VERSION ""

NS_ :

BS_:

BU_: ECU

VAL_TABLE_ Engine_Limiting_Functions 0 "None" 1 "Hard Rev Limiting" 2 "Soft Rev Limiting" 3 "Spark Retard Limiting" 4 "Boost Limiting" 5 "Nitrous Retard" 6 "Flat Shift" 7 "Traction Control" 8 "Launch Control" 9 "Anti-Lag" 10 "Engine Protection" 11 "3-Step Launch" 12 "Rolling Launch" 13 "Burn Out" 14 "Water Inj." 15 "Gear Shift Cut" 16 "RPM Window Switch" 17 "Torque Management" 18 "Overrun Boost" 19 "Idle Control" ;

VAL_TABLE_ Haltech_Special_Values_Gear 0 "Neutral" 1 "1st" 2 "2nd" 3 "3rd" 4 "4th" 5 "5th" 6 "6th" 7 "7th" 8 "8th" 9 "9th" 10 "10th" 11 "11th" 12 "12th" -1 "Reverse" ;

VAL_TABLE_ Traction_Control_States 0 "Disabled" 1 "Enabled" 2 "Active" 3 "Active & Enabled" ;

VAL_TABLE_ Boolean_States 0 "Off" 1 "On" ;

VAL_TABLE_ CAN_Error_Values 0 "Error" ;

VAL_TABLE_ Exhausted_Cutout_States -1 "Input Error" 0 "Disabled" 1 "Closed" 2 "Opening" 3 "Open" 4 "Closing" 5 "Paused Part Way" ;

VAL_TABLE_ Engine_Limiter_Method 0 "No Cut" 1 "Fuel" 2 "Ignition" 3 "Fuel and Ignition" ;

VAL_TABLE_ Cruise_Control_States 0 "Disabled" 1 "Inactive" 2 "Cruising" 3 "Accelerating" 4 "Decelerating" ;

VAL_TABLE_ Cruise_Control_Input_States 0 "Unused" 1 "Disable" 2 "Enable" 3 "Enable/Disable" 4 "Cancel" 8 "Set" 12 "Set/Cancel" 16 "Resume" 20 "Resume/Cancel" 32 "Accel" 64 "Decel" 76 "Set/Coast/Cancel" 84 "Resume/Coast/Cancel" 128 "Increment" 168 "Set/Accel/+" 176 "Resume/Accel/+" 256 "Decrement" 328 "Set/Coast/-" 336 "Resume/Coast/-" 512 "Rest Position" ;

VAL_TABLE_ ABS_States 0 "Not Armed" 1 "Armed" ;

VAL_TABLE_ ABS_Activity 0 "Inactive" 1 "Active" ;

VAL_TABLE_ ABS_Error 0 "OK" 1 "Error" ;

VAL_TABLE_ Pit_Lane_States 0 "Inactive" 1 "Active" ;

VAL_TABLE_ Pit_Lane_Error 0 "OK" 1 "Error" ;

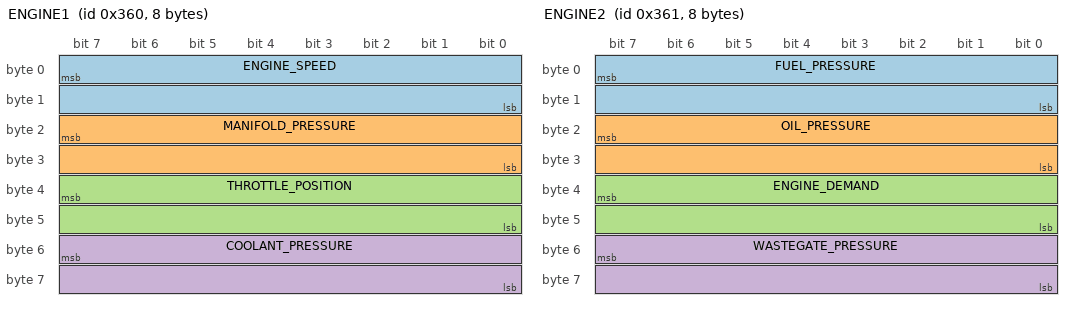
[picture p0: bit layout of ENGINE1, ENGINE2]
BO_ 864 ENGINE1: 8 ECU
 SG_ ENGINE_SPEED : 7|16@0+ (1,0) [0|65535] "RPM" ECU
 SG_ MANIFOLD_PRESSURE : 23|16@0+ (0.1,0) [0|6553.5] "kPa" ECU
 SG_ THROTTLE_POSITION : 39|16@0+ (0.1,0) [0|100] "%" ECU
 SG_ COOLANT_PRESSURE : 55|16@0+ (0.1,-101.3) [-101.3|6452.2] "kPa" ECU

BO_ 865 ENGINE2: 8 ECU
 SG_ FUEL_PRESSURE : 7|16@0+ (0.1,-101.3) [-101.3|6452.2] "kPa" ECU
 SG_ OIL_PRESSURE : 23|16@0+ (0.1,-101.3) [-101.3|6452.2] "kPa" ECU
 SG_ ENGINE_DEMAND : 39|16@0+ (0.1,0) [0|100] "%" ECU
 SG_ WASTEGATE_PRESSURE : 55|16@0+ (0.1,-101.3) [-101.3|6452.2] "kPa" ECU

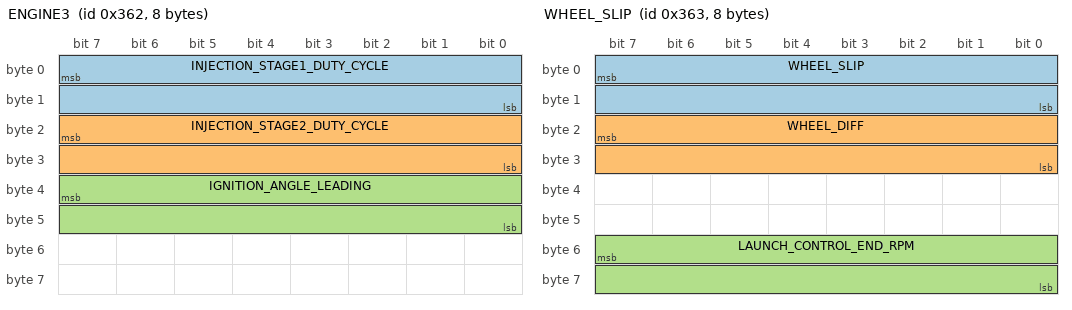
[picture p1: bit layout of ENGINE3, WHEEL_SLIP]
BO_ 866 ENGINE3: 8 ECU
 SG_ INJECTION_STAGE1_DUTY_CYCLE : 7|16@0+ (0.1,0) [0|100] "%" ECU
 SG_ INJECTION_STAGE2_DUTY_CYCLE : 23|16@0+ (0.1,0) [0|100] "%" ECU
 SG_ IGNITION_ANGLE_LEADING : 39|16@0- (0.1,0) [-3276.8|3276.7] "°" ECU

BO_ 867 WHEEL_SLIP: 8 ECU
 SG_ WHEEL_SLIP : 7|16@0- (0.1,0) [-3276.8|3276.7] "km/h" ECU
 SG_ WHEEL_DIFF : 23|16@0- (0.1,0) [-3276.8|3276.7] "km/h" ECU
 SG_ LAUNCH_CONTROL_END_RPM : 55|16@0+ (1,0) [0|65535] "RPM" ECU

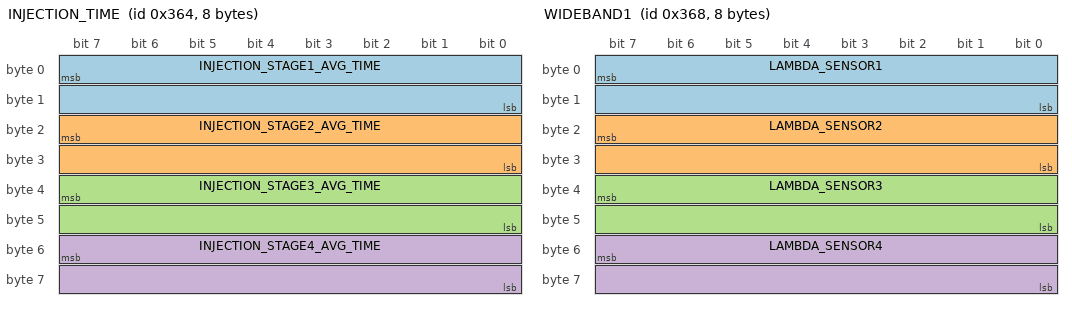
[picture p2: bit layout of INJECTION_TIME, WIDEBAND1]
BO_ 868 INJECTION_TIME: 8 ECU
 SG_ INJECTION_STAGE1_AVG_TIME : 7|16@0+ (0.001,0) [0|65.535] "ms" ECU
 SG_ INJECTION_STAGE2_AVG_TIME : 23|16@0+ (0.001,0) [0|65.535] "ms" ECU
 SG_ INJECTION_STAGE3_AVG_TIME : 39|16@0+ (0.001,0) [0|65.535] "ms" ECU
 SG_ INJECTION_STAGE4_AVG_TIME : 55|16@0+ (0.001,0) [0|65.535] "ms" ECU

BO_ 872 WIDEBAND1: 8 ECU
 SG_ LAMBDA_SENSOR1 : 7|16@0+ (0.001,0) [0|65.535] "λ" ECU
 SG_ LAMBDA_SENSOR2 : 23|16@0+ (0.001,0) [0|65.535] "λ" ECU
 SG_ LAMBDA_SENSOR3 : 39|16@0+ (0.001,0) [0|65.535] "λ" ECU
 SG_ LAMBDA_SENSOR4 : 55|16@0+ (0.001,0) [0|65.535] "λ" ECU

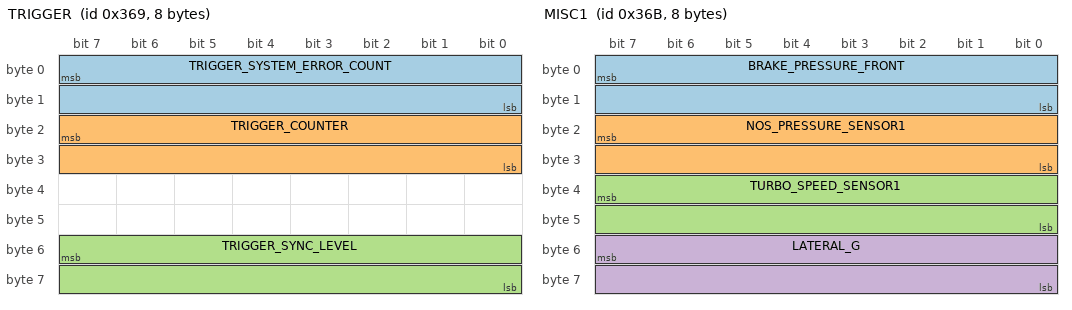
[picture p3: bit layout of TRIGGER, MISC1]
BO_ 873 TRIGGER: 8 ECU
 SG_ TRIGGER_SYSTEM_ERROR_COUNT : 7|16@0+ (1,0) [0|65535] "raw" ECU
 SG_ TRIGGER_COUNTER : 23|16@0+ (1,0) [0|65535] "raw" ECU
 SG_ TRIGGER_SYNC_LEVEL : 55|16@0+ (1,0) [0|65535] "raw" ECU

BO_ 874 KNOCK: 8 ECU
 SG_ KNOCK_LEVEL1 : 7|16@0+ (0.01,0) [0|655.35] "dB" ECU
 SG_ KNOCK_LEVEL2 : 23|16@0+ (0.01,0) [0|655.35] "dB" ECU

BO_ 875 MISC1: 8 ECU
 SG_ BRAKE_PRESSURE_FRONT : 7|16@0+ (1,-101.3) [-101.3|65433.7] "kPa" ECU
 SG_ NOS_PRESSURE_SENSOR1 : 23|16@0+ (0.22,-101.3) [-101.3|14316.4] "kPa" ECU
 SG_ TURBO_SPEED_SENSOR1 : 39|16@0+ (10,0) [0|655350] "RPM" ECU
 SG_ LATERAL_G : 55|16@0- (0.1,0) [-3276.8|3276.7] "m/s2" ECU

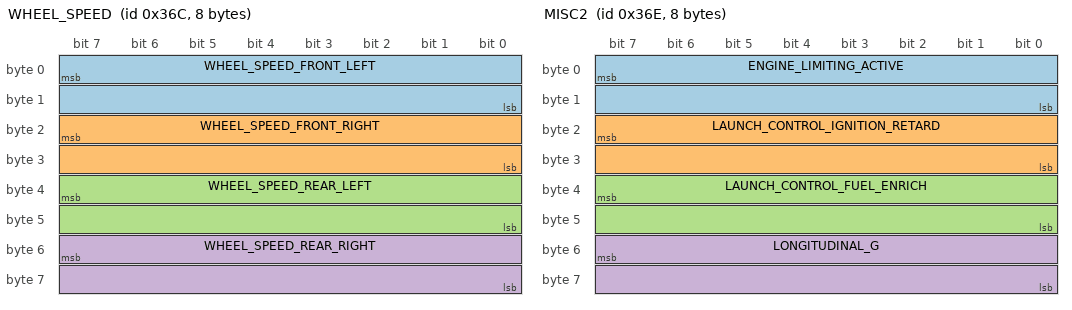
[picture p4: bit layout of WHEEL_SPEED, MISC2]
BO_ 876 WHEEL_SPEED: 8 ECU
 SG_ WHEEL_SPEED_FRONT_LEFT : 7|16@0+ (0.1,0) [0|6553.5] "km/h" ECU
 SG_ WHEEL_SPEED_FRONT_RIGHT : 23|16@0+ (0.1,0) [0|6553.5] "km/h" ECU
 SG_ WHEEL_SPEED_REAR_LEFT : 39|16@0+ (0.1,0) [0|6553.5] "km/h" ECU
 SG_ WHEEL_SPEED_REAR_RIGHT : 55|16@0+ (0.1,0) [0|6553.5] "km/h" ECU

BO_ 877 EXHAUST_CAM: 8 ECU
 SG_ EXHAUST_CAM_ANGLE1 : 39|16@0- (0.1,0) [-3276.8|3276.7] "°" ECU
 SG_ EXHAUST_CAM_ANGLE2 : 55|16@0- (0.1,0) [-3276.8|3276.7] "°" ECU

BO_ 878 MISC2: 8 ECU
 SG_ ENGINE_LIMITING_ACTIVE : 7|16@0+ (1,0) [0|1] "boolean" ECU
 SG_ LAUNCH_CONTROL_IGNITION_RETARD : 23|16@0- (0.1,0) [-3276.8|3276.7] "°" ECU
 SG_ LAUNCH_CONTROL_FUEL_ENRICH : 39|16@0- (0.1,0) [-3276.8|3276.7] "%" ECU
 SG_ LONGITUDINAL_G : 55|16@0- (0.1,0) [-3276.8|3276.7] "m/s2" ECU

BO_ 879 PWM_OUTPUT: 8 ECU
 SG_ GENERIC_OUTPUT1_DUTY_CYCLE : 7|16@0+ (0.1,0) [0|100] "%" ECU
 SG_ BOOST_CONTROL_OUTPUT : 23|16@0+ (0.1,0) [0|100] "%" ECU

BO_ 880 MISC3: 8 ECU
 SG_ VEHICLE_SPEED : 7|16@0+ (0.1,0) [0|6553.5] "km/h" ECU
 SG_ INTAKE_CAM_ANGLE1 : 39|16@0- (0.1,0) [-3276.8|3276.7] "°" ECU
 SG_ INTAKE_CAM_ANGLE2 : 55|16@0- (0.1,0) [-3276.8|3276.7] "°" ECU

BO_ 881 FUEL_FLOW: 8 ECU
 SG_ FUEL_FLOW : 7|16@0+ (1,0) [0|65535] "cc/min" ECU
 SG_ FUEL_FLOW_RETURN : 23|16@0+ (1,0) [0|65535] "cc/min" ECU

BO_ 882 MISC4: 8 ECU
 SG_ BATTERY_VOLTAGE : 7|16@0+ (0.1,0) [0|6553.5] "Volts" ECU
 SG_ TARGET_BOOST_LEVEL : 39|16@0+ (0.1,0) [0|6553.5] "kPa" ECU
 SG_ BAROMETRIC_PRESSURE : 55|16@0+ (0.1,0) [0|6553.5] "kPa" ECU

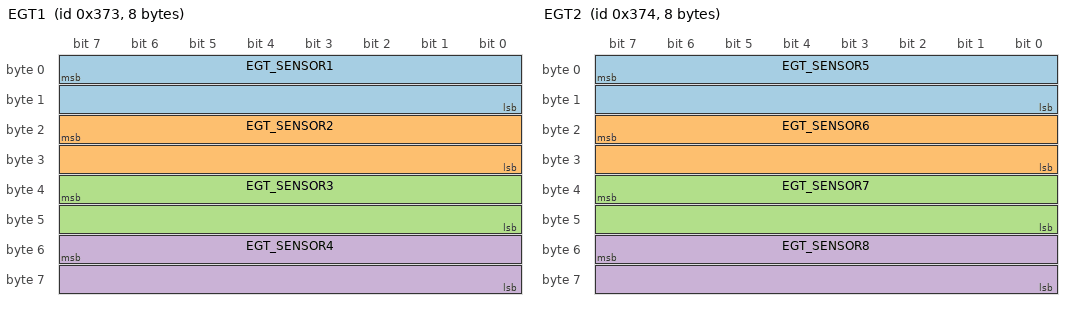
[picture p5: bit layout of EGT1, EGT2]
BO_ 883 EGT1: 8 ECU
 SG_ EGT_SENSOR1 : 7|16@0+ (0.1,0) [0|6553.5] "K" ECU
 SG_ EGT_SENSOR2 : 23|16@0+ (0.1,0) [0|6553.5] "K" ECU
 SG_ EGT_SENSOR3 : 39|16@0+ (0.1,0) [0|6553.5] "K" ECU
 SG_ EGT_SENSOR4 : 55|16@0+ (0.1,0) [0|6553.5] "K" ECU

BO_ 884 EGT2: 8 ECU
 SG_ EGT_SENSOR5 : 7|16@0+ (0.1,0) [0|6553.5] "K" ECU
 SG_ EGT_SENSOR6 : 23|16@0+ (0.1,0) [0|6553.5] "K" ECU
 SG_ EGT_SENSOR7 : 39|16@0+ (0.1,0) [0|6553.5] "K" ECU
 SG_ EGT_SENSOR8 : 55|16@0+ (0.1,0) [0|6553.5] "K" ECU

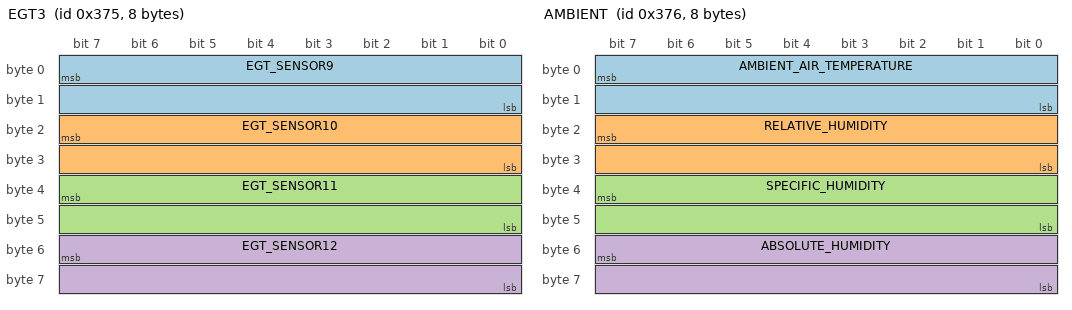
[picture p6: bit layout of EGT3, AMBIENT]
BO_ 885 EGT3: 8 ECU
 SG_ EGT_SENSOR9 : 7|16@0+ (0.1,0) [0|6553.5] "K" ECU
 SG_ EGT_SENSOR10 : 23|16@0+ (0.1,0) [0|6553.5] "K" ECU
 SG_ EGT_SENSOR11 : 39|16@0+ (0.1,0) [0|6553.5] "K" ECU
 SG_ EGT_SENSOR12 : 55|16@0+ (0.1,0) [0|6553.5] "K" ECU

BO_ 886 AMBIENT: 8 ECU
 SG_ AMBIENT_AIR_TEMPERATURE : 7|16@0+ (0.1,0) [0|6553.5] "K" ECU
 SG_ RELATIVE_HUMIDITY : 23|16@0- (0.1,0) [-3276.8|3276.7] "%" ECU
 SG_ SPECIFIC_HUMIDITY : 39|16@0+ (100,0) [0|6553500] "ppm" ECU
 SG_ ABSOLUTE_HUMIDITY : 55|16@0+ (0.1,0) [0|6553.5] "g/m3" ECU

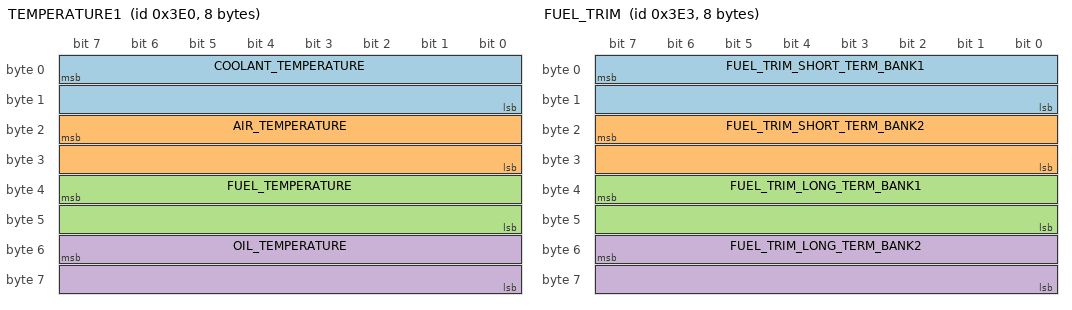
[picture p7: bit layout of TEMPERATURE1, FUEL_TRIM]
BO_ 992 TEMPERATURE1: 8 ECU
 SG_ COOLANT_TEMPERATURE : 7|16@0+ (0.1,0) [0|6553.5] "K" ECU
 SG_ AIR_TEMPERATURE : 23|16@0+ (0.1,0) [0|6553.5] "K" ECU
 SG_ FUEL_TEMPERATURE : 39|16@0+ (0.1,0) [0|6553.5] "K" ECU
 SG_ OIL_TEMPERATURE : 55|16@0+ (0.1,0) [0|6553.5] "K" ECU

BO_ 993 TEMPERATURE2: 8 ECU
 SG_ GEARBOX_OIL_TEMPERATURE : 7|16@0+ (0.1,0) [0|6553.5] "K" ECU
 SG_ DIFF_OIL_TEMPERATURE : 23|16@0+ (0.1,0) [0|6553.5] "K" ECU
 SG_ FUEL_COMPOSITION : 39|16@0+ (0.1,0) [0|100] "%" ECU

BO_ 994 FUEL_LEVEL: 8 ECU
 SG_ FUEL_LEVEL : 7|16@0+ (0.1,0) [0|6553.5] "L" ECU

BO_ 995 FUEL_TRIM: 8 ECU
 SG_ FUEL_TRIM_SHORT_TERM_BANK1 : 7|16@0- (0.1,0) [-3276.8|3276.7] "%" ECU
 SG_ FUEL_TRIM_SHORT_TERM_BANK2 : 23|16@0- (0.1,0) [-3276.8|3276.7] "%" ECU
 SG_ FUEL_TRIM_LONG_TERM_BANK1 : 39|16@0- (0.1,0) [-3276.8|3276.7] "%" ECU
 SG_ FUEL_TRIM_LONG_TERM_BANK2 : 55|16@0- (0.1,0) [-3276.8|3276.7] "%" ECU

BO_ 996 MISC5: 8 ECU
 SG_ NEUTRAL_SWITCH : 15|1@0+ (1,0) [0|1] "boolean" ECU
 SG_ REVERSE_SWITCH : 14|1@0+ (1,0) [0|1] "boolean" ECU
 SG_ GEAR_SWITCH : 13|1@0+ (1,0) [0|1] "boolean" ECU
 SG_ DECEL_CUT_ACTIVE : 12|1@0+ (1,0) [0|1] "boolean" ECU
 SG_ TRANSIENT_THROTTLE_ACTIVE : 11|1@0+ (1,0) [0|1] "boolean" ECU
 SG_ BRAKE_PEDAL_SWITCH : 10|1@0+ (1,0) [0|1] "boolean" ECU
 SG_ CLUTCH_SWITCH : 9|1@0+ (1,0) [0|1] "boolean" ECU
 SG_ OIL_PRESSURE_LIGHT : 8|1@0+ (1,0) [0|1] "boolean" ECU
 SG_ LAUNCH_CONTROL_ACTIVE : 23|1@0+ (1,0) [0|1] "boolean" ECU
 SG_ LAUNCH_CONTROL_SWITCH : 22|1@0+ (1,0) [0|1] "boolean" ECU
 SG_ AUX_RPM_LIMITER_ACTIVE : 21|1@0+ (1,0) [0|1] "boolean" ECU
 SG_ FLAT_SHIFT_SWITCH : 19|1@0+ (1,0) [0|1] "boolean" ECU
 SG_ TORQUE_REDUCTION_ACTIVE : 17|1@0+ (1,0) [0|1] "boolean" ECU
 SG_ TRACTION_CONTROL_ENABLED : 31|1@0+ (1,0) [0|1] "boolean" ECU
 SG_ TRACTION_CONTROL_ACTIVE : 30|1@0+ (1,0) [0|1] "boolean" ECU
 SG_ AIR_CON_REQUEST : 29|1@0+ (1,0) [0|1] "boolean" ECU
 SG_ AIR_CON_OUTPUT : 28|1@0+ (1,0) [0|1] "boolean" ECU
 SG_ THERMO_FAN4_ON : 27|1@0+ (1,0) [0|1] "boolean" ECU
 SG_ THERMO_FAN3_ON : 26|1@0+ (1,0) [0|1] "boolean" ECU
 SG_ THERMO_FAN2_ON : 25|1@0+ (1,0) [0|1] "boolean" ECU
 SG_ THERMO_FAN1_ON : 24|1@0+ (1,0) [0|1] "boolean" ECU
 SG_ ROTARY_TRIM_POT1 : 39|8@0- (1,0) [-128|127] "raw" ECU
 SG_ ROTARY_TRIM_POT2 : 47|8@0- (1,0) [-128|127] "raw" ECU
 SG_ ROTARY_TRIM_POT3 : 55|8@0- (1,0) [-128|127] "raw" ECU
 SG_ CHECK_ENGINE_LIGHT : 63|1@0+ (1,0) [0|1] "boolean" ECU
 SG_ BATTERY_LIGHT_ACTIVE : 62|1@0+ (1,0) [0|1] "boolean" ECU
 SG_ HAND_BRAKE_STATE : 57|1@0+ (1,0) [0|1] "boolean" ECU
 SG_ TRACTION_CONTROL_LIGHT : 56|1@0+ (1,0) [0|1] "boolean" ECU

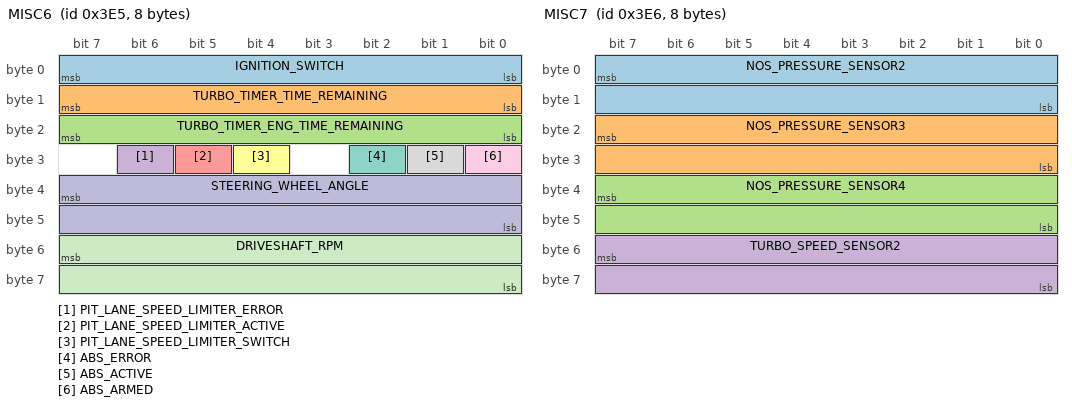
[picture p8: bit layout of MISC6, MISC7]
BO_ 997 MISC6: 8 ECU
 SG_ IGNITION_SWITCH : 7|8@0+ (1,0) [0|1] "boolean" ECU
 SG_ TURBO_TIMER_TIME_REMAINING : 15|8@0+ (1,0) [0|255] "s" ECU
 SG_ TURBO_TIMER_ENG_TIME_REMAINING : 23|8@0+ (1,0) [0|255] "s" ECU
 SG_ PIT_LANE_SPEED_LIMITER_ERROR : 30|1@0+ (1,0) [0|1] "enum" ECU
 SG_ PIT_LANE_SPEED_LIMITER_ACTIVE : 29|1@0+ (1,0) [0|1] "enum" ECU
 SG_ PIT_LANE_SPEED_LIMITER_SWITCH : 28|1@0+ (1,0) [0|1] "boolean" ECU
 SG_ ABS_ERROR : 26|1@0+ (1,0) [0|1] "enum" ECU
 SG_ ABS_ACTIVE : 25|1@0+ (1,0) [0|1] "enum" ECU
 SG_ ABS_ARMED : 24|1@0+ (1,0) [0|1] "enum" ECU
 SG_ STEERING_WHEEL_ANGLE : 39|16@0- (0.1,0) [-3276.8|3276.7] "°" ECU
 SG_ DRIVESHAFT_RPM : 55|16@0+ (1,0) [0|65535] "RPM" ECU

BO_ 998 MISC7: 8 ECU
 SG_ NOS_PRESSURE_SENSOR2 : 7|16@0+ (0.22,-101.3) [-101.3|14316.4] "kPa" ECU
 SG_ NOS_PRESSURE_SENSOR3 : 23|16@0+ (0.22,-101.3) [-101.3|14316.4] "kPa" ECU
 SG_ NOS_PRESSURE_SENSOR4 : 39|16@0+ (0.22,-101.3) [-101.3|14316.4] "kPa" ECU
 SG_ TURBO_SPEED_SENSOR2 : 55|16@0+ (10,0) [0|655350] "RPM" ECU

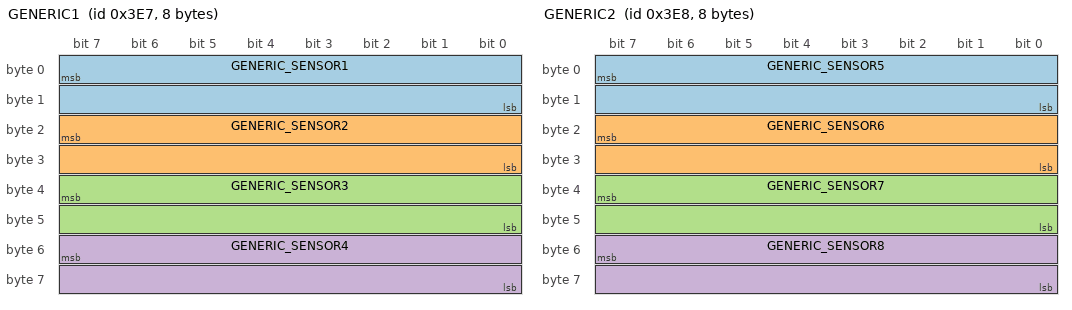
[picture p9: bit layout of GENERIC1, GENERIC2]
BO_ 999 GENERIC1: 8 ECU
 SG_ GENERIC_SENSOR1 : 7|16@0+ (1,0) [0|65535] "" ECU
 SG_ GENERIC_SENSOR2 : 23|16@0+ (1,0) [0|65535] "" ECU
 SG_ GENERIC_SENSOR3 : 39|16@0+ (1,0) [0|65535] "" ECU
 SG_ GENERIC_SENSOR4 : 55|16@0+ (1,0) [0|65535] "" ECU

BO_ 1000 GENERIC2: 8 ECU
 SG_ GENERIC_SENSOR5 : 7|16@0+ (1,0) [0|65535] "" ECU
 SG_ GENERIC_SENSOR6 : 23|16@0+ (1,0) [0|65535] "" ECU
 SG_ GENERIC_SENSOR7 : 39|16@0+ (1,0) [0|65535] "" ECU
 SG_ GENERIC_SENSOR8 : 55|16@0+ (1,0) [0|65535] "" ECU

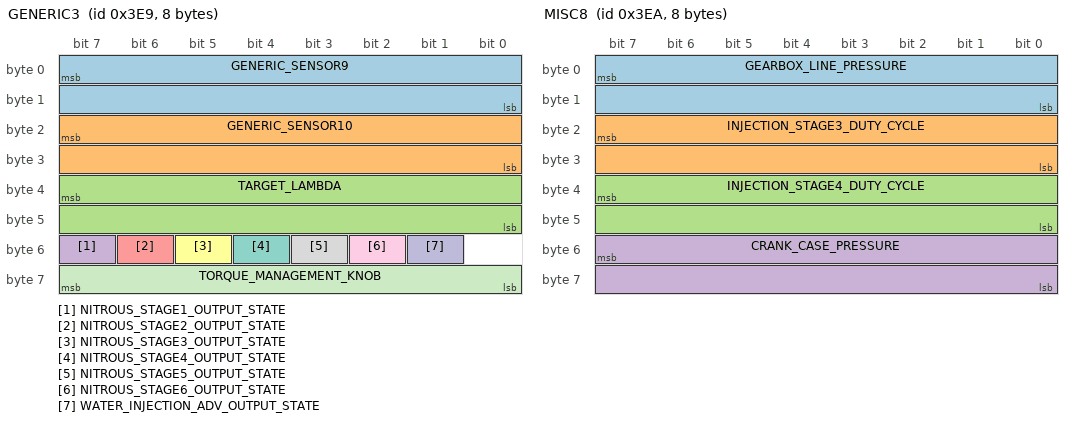
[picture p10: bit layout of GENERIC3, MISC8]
BO_ 1001 GENERIC3: 8 ECU
 SG_ GENERIC_SENSOR9 : 7|16@0+ (1,0) [0|65535] "" ECU
 SG_ GENERIC_SENSOR10 : 23|16@0+ (1,0) [0|65535] "" ECU
 SG_ TARGET_LAMBDA : 39|16@0+ (0.001,0) [0|65.535] "λ" ECU
 SG_ NITROUS_STAGE1_OUTPUT_STATE : 55|1@0+ (1,0) [0|1] "boolean" ECU
 SG_ NITROUS_STAGE2_OUTPUT_STATE : 54|1@0+ (1,0) [0|1] "boolean" ECU
 SG_ NITROUS_STAGE3_OUTPUT_STATE : 53|1@0+ (1,0) [0|1] "boolean" ECU
 SG_ NITROUS_STAGE4_OUTPUT_STATE : 52|1@0+ (1,0) [0|1] "boolean" ECU
 SG_ NITROUS_STAGE5_OUTPUT_STATE : 51|1@0+ (1,0) [0|1] "boolean" ECU
 SG_ NITROUS_STAGE6_OUTPUT_STATE : 50|1@0+ (1,0) [0|1] "boolean" ECU
 SG_ WATER_INJECTION_ADV_OUTPUT_STATE : 49|1@0+ (1,0) [0|1] "boolean" ECU
 SG_ TORQUE_MANAGEMENT_KNOB : 63|8@0- (1,0) [-128|127] "raw" ECU

BO_ 1002 MISC8: 8 ECU
 SG_ GEARBOX_LINE_PRESSURE : 7|16@0+ (0.1,-101.3) [-101.3|6452.2] "kPa" ECU
 SG_ INJECTION_STAGE3_DUTY_CYCLE : 23|16@0+ (0.1,0) [0|100] "%" ECU
 SG_ INJECTION_STAGE4_DUTY_CYCLE : 39|16@0+ (0.1,0) [0|100] "%" ECU
 SG_ CRANK_CASE_PRESSURE : 55|16@0+ (0.1,-101.3) [-101.3|6452.2] "kPa" ECU

BO_ 1003 MISC9: 8 ECU
 SG_ RACE_TIMER : 7|32@0+ (1,0) [0|4294967295] "ms" ECU
 SG_ IGNITION_ANGLE_BANK1 : 39|16@0- (0.1,0) [-3276.8|3276.7] "°" ECU
 SG_ IGNITION_ANGLE_BANK2 : 55|16@0- (0.1,0) [-3276.8|3276.7] "°" ECU

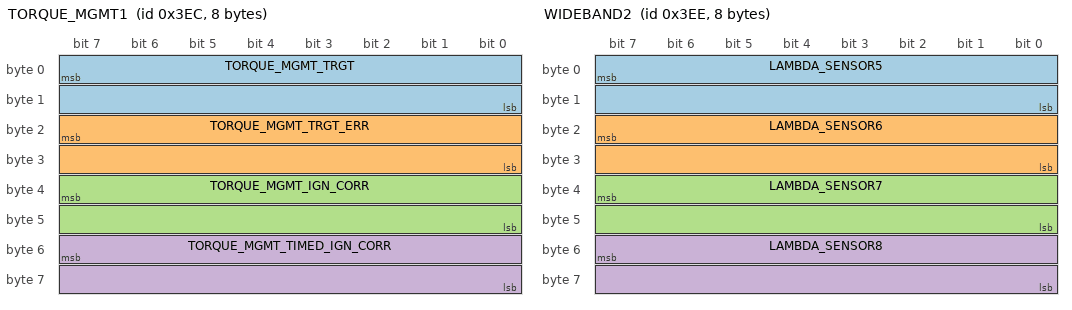
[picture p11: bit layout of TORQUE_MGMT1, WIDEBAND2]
BO_ 1004 TORQUE_MGMT1: 8 ECU
 SG_ TORQUE_MGMT_TRGT : 7|16@0- (1,0) [-32768|32767] "RPM" ECU
 SG_ TORQUE_MGMT_TRGT_ERR : 23|16@0- (1,0) [-32768|32767] "RPM" ECU
 SG_ TORQUE_MGMT_IGN_CORR : 39|16@0- (0.1,0) [-3276.8|3276.7] "°" ECU
 SG_ TORQUE_MGMT_TIMED_IGN_CORR : 55|16@0- (0.1,0) [-3276.8|3276.7] "°" ECU

BO_ 1005 TORQUE_MGMT2: 8 ECU
 SG_ TORQUE_MGMT_COMBINED_IGN_CORR : 7|16@0- (0.1,0) [-3276.8|3276.7] "°" ECU

BO_ 1006 WIDEBAND2: 8 ECU
 SG_ LAMBDA_SENSOR5 : 7|16@0+ (0.001,0) [0|65.535] "λ" ECU
 SG_ LAMBDA_SENSOR6 : 23|16@0+ (0.001,0) [0|65.535] "λ" ECU
 SG_ LAMBDA_SENSOR7 : 39|16@0+ (0.001,0) [0|65.535] "λ" ECU
 SG_ LAMBDA_SENSOR8 : 55|16@0+ (0.001,0) [0|65.535] "λ" ECU

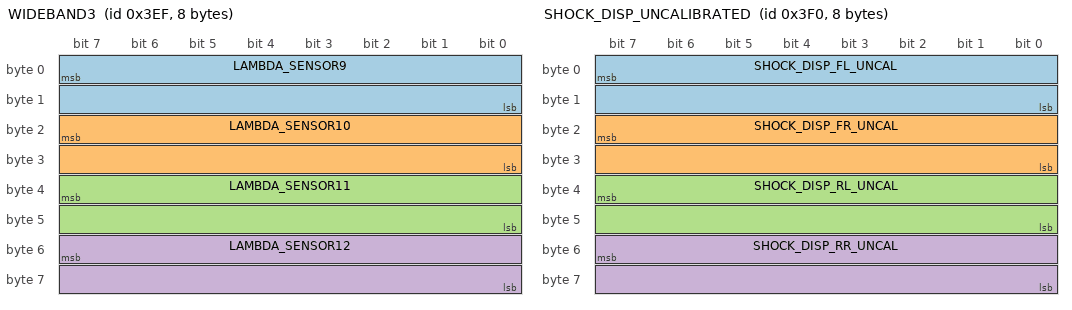
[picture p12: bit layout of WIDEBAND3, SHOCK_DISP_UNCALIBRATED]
BO_ 1007 WIDEBAND3: 8 ECU
 SG_ LAMBDA_SENSOR9 : 7|16@0+ (0.001,0) [0|65.535] "λ" ECU
 SG_ LAMBDA_SENSOR10 : 23|16@0+ (0.001,0) [0|65.535] "λ" ECU
 SG_ LAMBDA_SENSOR11 : 39|16@0+ (0.001,0) [0|65.535] "λ" ECU
 SG_ LAMBDA_SENSOR12 : 55|16@0+ (0.001,0) [0|65.535] "λ" ECU

BO_ 1008 SHOCK_DISP_UNCALIBRATED: 8 ECU
 SG_ SHOCK_DISP_FL_UNCAL : 7|16@0+ (0.1,0) [0|6553.5] "mm" ECU
 SG_ SHOCK_DISP_FR_UNCAL : 23|16@0+ (0.1,0) [0|6553.5] "mm" ECU
 SG_ SHOCK_DISP_RL_UNCAL : 39|16@0+ (0.1,0) [0|6553.5] "mm" ECU
 SG_ SHOCK_DISP_RR_UNCAL : 55|16@0+ (0.1,0) [0|6553.5] "mm" ECU

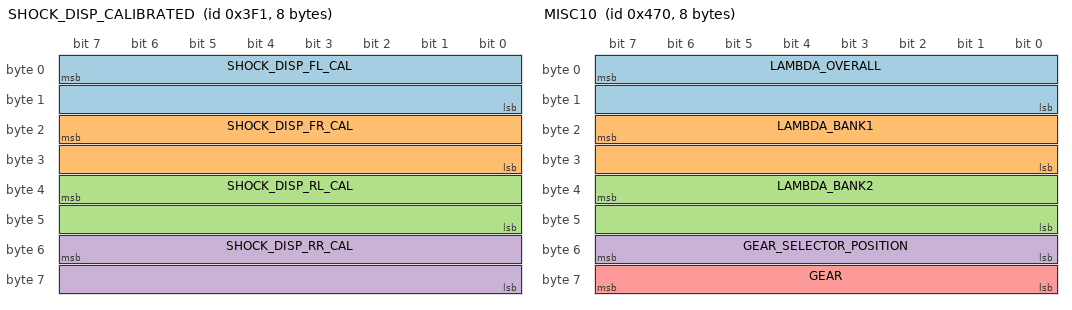
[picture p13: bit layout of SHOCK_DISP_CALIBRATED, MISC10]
BO_ 1009 SHOCK_DISP_CALIBRATED: 8 ECU
 SG_ SHOCK_DISP_FL_CAL : 7|16@0- (0.1,0) [-3276.8|3276.7] "mm" ECU
 SG_ SHOCK_DISP_FR_CAL : 23|16@0- (0.1,0) [-3276.8|3276.7] "mm" ECU
 SG_ SHOCK_DISP_RL_CAL : 39|16@0- (0.1,0) [-3276.8|3276.7] "mm" ECU
 SG_ SHOCK_DISP_RR_CAL : 55|16@0- (0.1,0) [-3276.8|3276.7] "mm" ECU

BO_ 1129 ECU_TEMPERATURE: 8 ECU
 SG_ ECU_TEMPERATURE : 7|16@0+ (0.1,0) [0|6553.5] "K" ECU

BO_ 1136 MISC10: 8 ECU
 SG_ LAMBDA_OVERALL : 7|16@0+ (0.001,0) [0|65.535] "λ" ECU
 SG_ LAMBDA_BANK1 : 23|16@0+ (0.001,0) [0|65.535] "λ" ECU
 SG_ LAMBDA_BANK2 : 39|16@0+ (0.001,0) [0|65.535] "λ" ECU
 SG_ GEAR_SELECTOR_POSITION : 55|8@0- (1,0) [-128|127] "enum" ECU
 SG_ GEAR : 63|8@0- (1,0) [-128|127] "enum" ECU

BO_ 1137 MISC11: 8 ECU
 SG_ INJECTOR_PRESSURE_DIFFERENTIAL : 7|16@0- (0.1,0) [-3276.8|3276.7] "kPa" ECU
 SG_ ACCELERATOR_PEDAL_POSITION : 23|16@0+ (0.1,0) [0|100] "%" ECU
 SG_ EXHAUST_MANIFOLD_PRESSURE : 39|16@0+ (0.1,0) [0|6553.5] "kPa" ECU

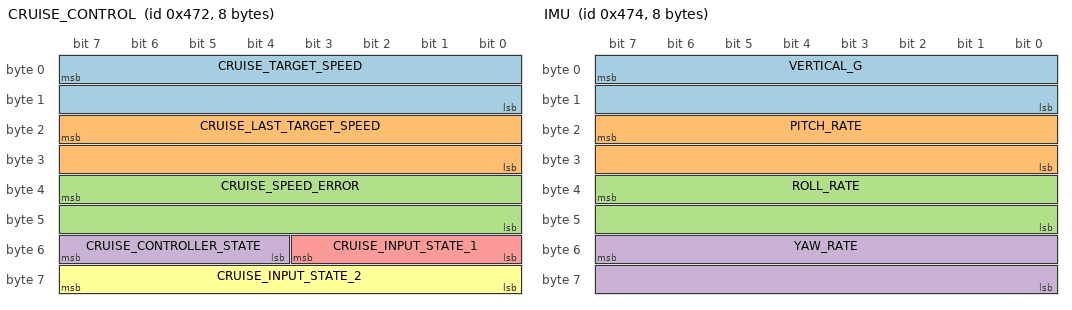
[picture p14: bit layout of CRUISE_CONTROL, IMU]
BO_ 1138 CRUISE_CONTROL: 8 ECU
 SG_ CRUISE_TARGET_SPEED : 7|16@0+ (0.1,0) [0|6553.5] "km/h" ECU
 SG_ CRUISE_LAST_TARGET_SPEED : 23|16@0+ (0.1,0) [0|6553.5] "km/h" ECU
 SG_ CRUISE_SPEED_ERROR : 39|16@0- (0.1,0) [-3276.8|3276.7] "km/h" ECU
 SG_ CRUISE_CONTROLLER_STATE : 55|4@0+ (1,0) [0|15] "enum" ECU
 SG_ CRUISE_INPUT_STATE_1 : 51|4@0+ (1,0) [0|15] "bit-field" ECU
 SG_ CRUISE_INPUT_STATE_2 : 63|8@0+ (1,0) [0|255] "bit-field" Vector__XXX

BO_ 1139 MISC12: 8 ECU
 SG_ TOTAL_FUEL_USED : 7|32@0+ (1,0) [0|4294967295] "cc" ECU
 SG_ ROLLING_ANTILAG_SWITCH : 39|1@0+ (1,0) [0|1] "raw" ECU
 SG_ ANTILAG_SWITCH : 38|1@0+ (1,0) [0|1] "raw" ECU
 SG_ ANTILAG_OUTPUT : 37|1@0+ (1,0) [0|1] "boolean" ECU
 SG_ TC_SWITCH : 36|1@0+ (1,0) [0|1] "boolean" ECU
 SG_ PRIMARY_FUEL_PUMP_OUTPUT : 35|1@0+ (1,0) [0|1] "boolean" Vector__XXX
 SG_ AUX1_FUEL_PUMP_OUTPUT : 34|1@0+ (1,0) [0|1] "boolean" Vector__XXX
 SG_ AUX2_FUEL_PUMP_OUTPUT : 33|1@0+ (1,0) [0|1] "boolean" Vector__XXX
 SG_ AUX3_FUEL_PUMP_OUTPUT : 32|1@0+ (1,0) [0|1] "boolean" Vector__XXX
 SG_ NITROUS_ENABLE1_SWITCH : 47|1@0+ (1,0) [0|1] "boolean" Vector__XXX
 SG_ NITROUS_ENABLE1_OUTPUT : 46|1@0+ (1,0) [0|1] "boolean" Vector__XXX
 SG_ NITROUS_ENABLE2_SWITCH : 45|1@0+ (1,0) [0|1] "boolean" Vector__XXX
 SG_ NITROUS_ENABLE2_OUTPUT : 44|1@0+ (1,0) [0|1] "boolean" Vector__XXX
 SG_ NITROUS_ENABLE3_SWITCH : 43|1@0+ (1,0) [0|1] "boolean" Vector__XXX
 SG_ NITROUS_ENABLE3_OUTPUT : 42|1@0+ (1,0) [0|1] "boolean" Vector__XXX
 SG_ NITROUS_ENABLE4_SWITCH : 41|1@0+ (1,0) [0|1] "boolean" Vector__XXX
 SG_ NITROUS_ENABLE4_OUTPUT : 40|1@0+ (1,0) [0|1] "boolean" Vector__XXX
 SG_ NITROUS_OVERIDE1_SWITCH : 55|1@0+ (1,0) [0|1] "boolean" Vector__XXX
 SG_ NITROUS_OVERIDE1_OUTPUT : 54|1@0+ (1,0) [0|1] "boolean" Vector__XXX
 SG_ NITROUS_OVERIDE2_SWITCH : 53|1@0+ (1,0) [0|1] "boolean" Vector__XXX
 SG_ NITROUS_OVERIDE2_OUTPUT : 52|1@0+ (1,0) [0|1] "boolean" Vector__XXX
 SG_ NITROUS_OVERIDE3_SWITCH : 51|1@0+ (1,0) [0|1] "boolean" Vector__XXX
 SG_ NITROUS_OVERIDE3_OUTPUT : 50|1@0+ (1,0) [0|1] "boolean" Vector__XXX
 SG_ NITROUS_OVERIDE4_SWITCH : 49|1@0+ (1,0) [0|1] "boolean" Vector__XXX
 SG_ NITROUS_OVERIDE4_OUTPUT : 48|1@0+ (1,0) [0|1] "boolean" Vector__XXX
 SG_ WATER_INJ_ADV_ENABLE_SWITCH : 63|1@0+ (1,0) [0|1] "boolean" Vector__XXX
 SG_ WATER_INJ_ADV_ENABLE_OUTPUT : 62|1@0+ (1,0) [0|1] "boolean" Vector__XXX
 SG_ WATER_INJ_ADV_OVERRIDE_SWITCH : 61|1@0+ (1,0) [0|1] "boolean" Vector__XXX
 SG_ WATER_INJ_ADV_OVERRIDE_OUTPUT : 60|1@0+ (1,0) [0|1] "boolean" Vector__XXX
 SG_ CUT_PERCENTAGE_METHOD : 59|4@0+ (1,0) [0|3] "enum" Vector__XXX

BO_ 1140 IMU: 8 ECU
 SG_ VERTICAL_G : 7|16@0- (0.1,0) [-3276.8|3276.7] "m/s2" ECU
 SG_ PITCH_RATE : 23|16@0- (0.1,0) [-3276.8|3276.7] "deg/s" ECU
 SG_ ROLL_RATE : 39|16@0- (0.1,0) [-3276.8|3276.7] "deg/s" ECU
 SG_ YAW_RATE : 55|16@0- (0.1,0) [-3276.8|3276.7] "deg/s" ECU

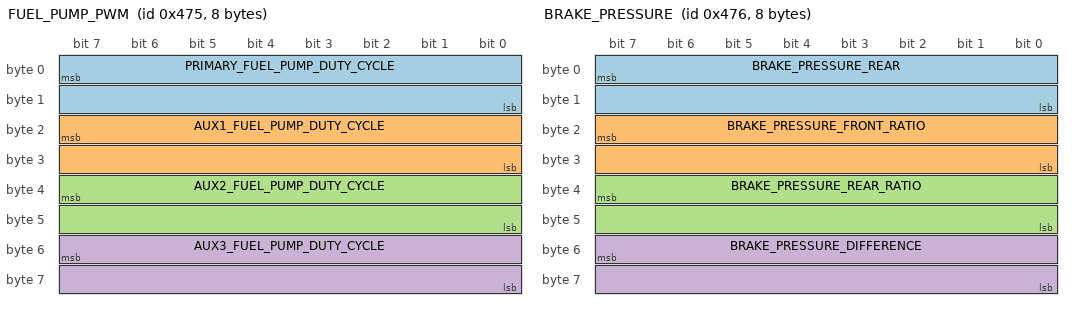
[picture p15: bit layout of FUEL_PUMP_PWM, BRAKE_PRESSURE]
BO_ 1141 FUEL_PUMP_PWM: 8 ECU
 SG_ PRIMARY_FUEL_PUMP_DUTY_CYCLE : 7|16@0+ (0.1,0) [0|100] "%" ECU
 SG_ AUX1_FUEL_PUMP_DUTY_CYCLE : 23|16@0+ (0.1,0) [0|100] "%" ECU
 SG_ AUX2_FUEL_PUMP_DUTY_CYCLE : 39|16@0+ (0.1,0) [0|100] "%" ECU
 SG_ AUX3_FUEL_PUMP_DUTY_CYCLE : 55|16@0+ (0.1,0) [0|100] "%" ECU

BO_ 1142 BRAKE_PRESSURE: 8 ECU
 SG_ BRAKE_PRESSURE_REAR : 7|16@0+ (1,-101.3) [-101.3|65433.7] "kPa" ECU
 SG_ BRAKE_PRESSURE_FRONT_RATIO : 23|16@0+ (0.1,0) [0|100] "%" ECU
 SG_ BRAKE_PRESSURE_REAR_RATIO : 39|16@0+ (0.1,0) [0|100] "%" ECU
 SG_ BRAKE_PRESSURE_DIFFERENCE : 55|16@0- (1,0) [-32768|32767] "kPa" ECU

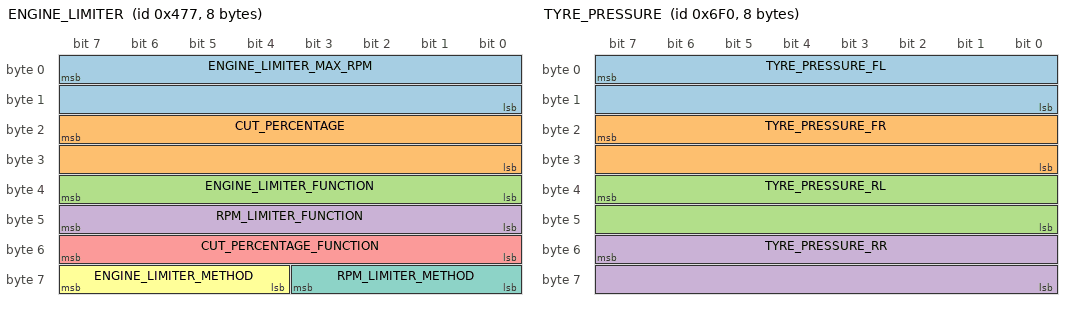
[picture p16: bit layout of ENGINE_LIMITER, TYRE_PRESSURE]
BO_ 1143 ENGINE_LIMITER: 8 ECU
 SG_ ENGINE_LIMITER_MAX_RPM : 7|16@0+ (1,0) [0|65535] "RPM" ECU
 SG_ CUT_PERCENTAGE : 23|16@0+ (0.1,0) [0|25.5] "%" ECU
 SG_ ENGINE_LIMITER_FUNCTION : 39|8@0+ (1,0) [0|255] "enum" ECU
 SG_ RPM_LIMITER_FUNCTION : 47|8@0+ (1,0) [0|255] "enum" ECU
 SG_ CUT_PERCENTAGE_FUNCTION : 55|8@0+ (1,0) [0|255] "enum" ECU
 SG_ ENGINE_LIMITER_METHOD : 63|4@0+ (1,0) [0|4] "enum" ECU
 SG_ RPM_LIMITER_METHOD : 59|4@0+ (1,0) [0|4] "enum" Vector__XXX

BO_ 1776 TYRE_PRESSURE: 8 ECU
 SG_ TYRE_PRESSURE_FL : 7|16@0+ (0.1,-101.3) [-101.3|6452.2] "kPa" ECU
 SG_ TYRE_PRESSURE_FR : 23|16@0+ (0.1,-101.3) [-101.3|6452.2] "kPa" ECU
 SG_ TYRE_PRESSURE_RL : 39|16@0+ (0.1,-101.3) [-101.3|6452.2] "kPa" ECU
 SG_ TYRE_PRESSURE_RR : 55|16@0+ (0.1,-101.3) [-101.3|6452.2] "kPa" ECU

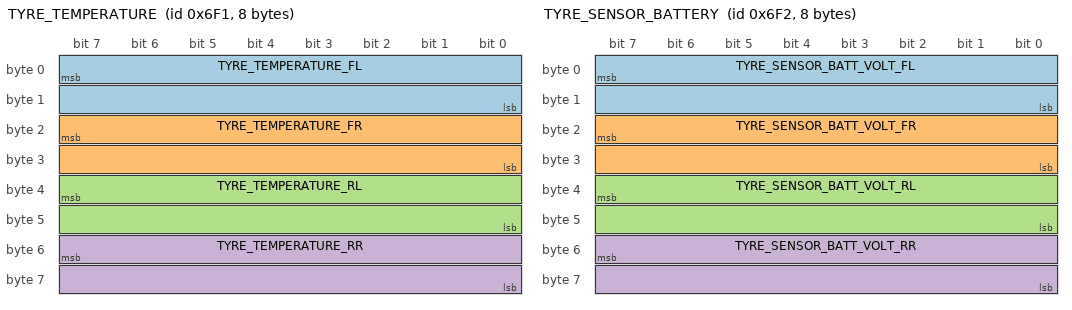
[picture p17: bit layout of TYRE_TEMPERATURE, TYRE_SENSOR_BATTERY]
BO_ 1777 TYRE_TEMPERATURE: 8 ECU
 SG_ TYRE_TEMPERATURE_FL : 7|16@0+ (0.1,0) [0|6553.5] "K" ECU
 SG_ TYRE_TEMPERATURE_FR : 23|16@0+ (0.1,0) [0|6553.5] "K" ECU
 SG_ TYRE_TEMPERATURE_RL : 39|16@0+ (0.1,0) [0|6553.5] "K" ECU
 SG_ TYRE_TEMPERATURE_RR : 55|16@0+ (0.1,0) [0|6553.5] "K" ECU

BO_ 1778 TYRE_SENSOR_BATTERY: 8 ECU
 SG_ TYRE_SENSOR_BATT_VOLT_FL : 7|16@0+ (0.001,0) [0|65.535] "V" ECU
 SG_ TYRE_SENSOR_BATT_VOLT_FR : 23|16@0+ (0.001,0) [0|65.535] "V" ECU
 SG_ TYRE_SENSOR_BATT_VOLT_RL : 39|16@0+ (0.001,0) [0|65.535] "V" ECU
 SG_ TYRE_SENSOR_BATT_VOLT_RR : 55|16@0+ (0.001,0) [0|65.535] "V" ECU

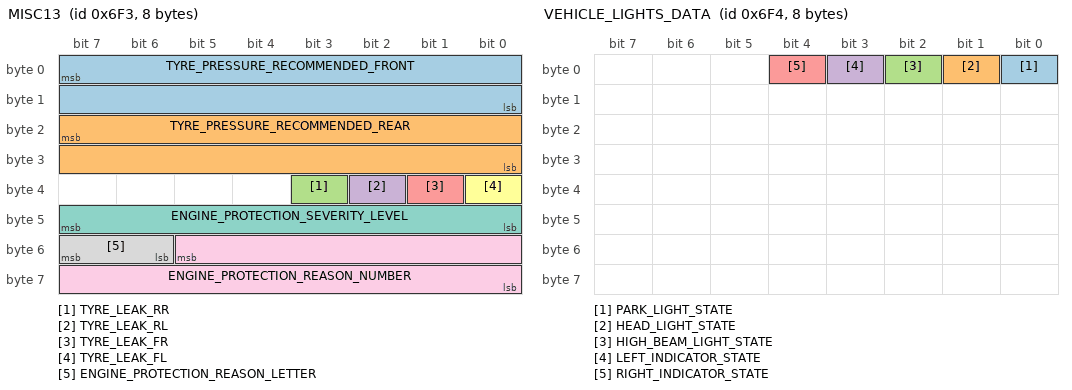
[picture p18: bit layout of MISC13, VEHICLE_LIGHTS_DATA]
BO_ 1779 MISC13: 8 ECU
 SG_ TYRE_PRESSURE_RECOMMENDED_FRONT : 7|16@0+ (0.1,-101.3) [-101.3|6452.2] "kPa" ECU
 SG_ TYRE_PRESSURE_RECOMMENDED_REAR : 23|16@0+ (0.1,-101.3) [-101.3|6452.2] "kPa" ECU
 SG_ TYRE_LEAK_RR : 35|1@0+ (1,0) [0|1] "boolean" ECU
 SG_ TYRE_LEAK_RL : 34|1@0+ (1,0) [0|1] "boolean" ECU
 SG_ TYRE_LEAK_FR : 33|1@0+ (1,0) [0|1] "boolean" ECU
 SG_ TYRE_LEAK_FL : 32|1@0+ (1,0) [0|1] "boolean" ECU
 SG_ ENGINE_PROTECTION_SEVERITY_LEVEL : 47|8@0+ (1,0) [0|3] "raw" ECU
 SG_ ENGINE_PROTECTION_REASON_LETTER : 55|2@0+ (1,0) [0|3] "enum" ECU
 SG_ ENGINE_PROTECTION_REASON_NUMBER : 53|14@0+ (1,0) [0|4096] "enum" Vector__XXX

BO_ 1780 VEHICLE_LIGHTS_DATA: 8 ECU
 SG_ PARK_LIGHT_STATE : 0|1@0+ (1,0) [0|1] "boolean" ECU
 SG_ HEAD_LIGHT_STATE : 1|1@0+ (1,0) [0|1] "boolean" ECU
 SG_ HIGH_BEAM_LIGHT_STATE : 2|1@0+ (1,0) [0|1] "boolean" ECU
 SG_ LEFT_INDICATOR_STATE : 3|1@0+ (1,0) [0|1] "boolean" ECU
 SG_ RIGHT_INDICATOR_STATE : 4|1@0+ (1,0) [0|1] "boolean" ECU

BO_ 1782 TRIP_METER: 8 ECU
 SG_ TOTAL_FUEL_USED_TRIP_METER1 : 7|32@0- (1,0) [-2147483648|2147483647] "cc" ECU
 SG_ DISTANCE_TRIP_METER1 : 39|32@0- (1,0) [-2147483648|2147483647] "m" ECU

BO_ 1783 MISC14: 8 ECU
 SG_ GENERIC_OUTPUT_STATES : 7|32@0+ (1,0) [0|4294967295] "bit-field" ECU
 SG_ CALCULATED_AIR_TEMPERATURE : 39|16@0+ (0.1,0) [0|6553.5] "K" ECU
 SG_ WATER_INJ_ADV_PWM : 55|16@0+ (0.1,0) [0|100] "%" ECU

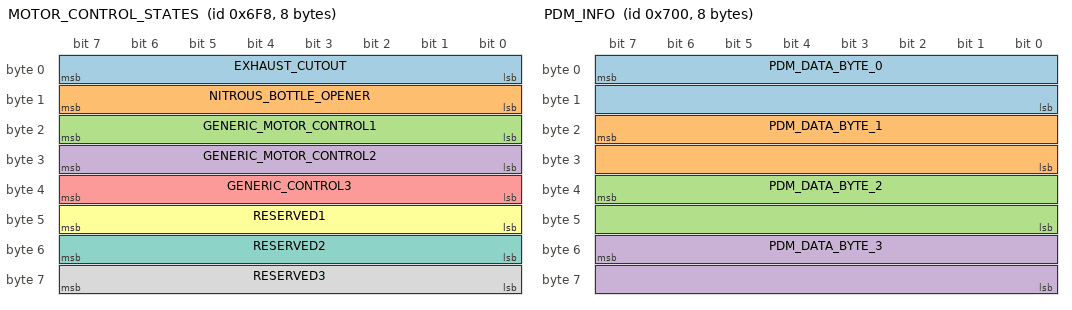
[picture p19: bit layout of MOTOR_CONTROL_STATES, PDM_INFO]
BO_ 1784 MOTOR_CONTROL_STATES: 8 ECU
 SG_ EXHAUST_CUTOUT : 7|8@0- (1,0) [-128|127] "enum" ECU
 SG_ NITROUS_BOTTLE_OPENER : 15|8@0- (1,0) [-128|127] "enum" ECU
 SG_ GENERIC_MOTOR_CONTROL1 : 23|8@0- (1,0) [-128|127] "enum" ECU
 SG_ GENERIC_MOTOR_CONTROL2 : 31|8@0- (1,0) [-128|127] "enum" ECU
 SG_ GENERIC_CONTROL3 : 39|8@0- (1,0) [-128|127] "enum" ECU
 SG_ RESERVED1 : 47|8@0+ (1,0) [0|255] "" Vector__XXX
 SG_ RESERVED2 : 55|8@0+ (1,0) [0|255] "" Vector__XXX
 SG_ RESERVED3 : 63|8@0+ (1,0) [0|255] "" Vector__XXX

BO_ 1792 PDM_INFO: 8 ECU
 SG_ PDM_DATA_BYTE_0 : 7|16@0+ (1,0) [0|65535] "" ECU
 SG_ PDM_DATA_BYTE_1 : 23|16@0+ (1,0) [0|65535] "" ECU
 SG_ PDM_DATA_BYTE_2 : 39|16@0+ (1,0) [0|65535] "" ECU
 SG_ PDM_DATA_BYTE_3 : 55|16@0+ (1,0) [0|65535] "" ECU

CM_ SG_ 996 TRACTION_CONTROL_LIGHT "See Traction Control States section.";
CM_ SG_ 996 TRACTION_CONTROL_ENABLED "See Traction Control States section.";
CM_ SG_ 996 TRACTION_CONTROL_ACTIVE "See Traction Control States section.";
CM_ BO_ 997 "Ignition switch and turbo timer data";
CM_ SG_ 997 PIT_LANE_SPEED_LIMITER_SWITCH "0=Off, 1=On";
CM_ SG_ 997 PIT_LANE_SPEED_LIMITER_ACTIVE "0=Inactive, 1=Active";
CM_ SG_ 997 PIT_LANE_SPEED_LIMITER_ERROR "0=OK, 1=Error";
CM_ SG_ 997 ABS_ARMED "0=Not Armed, 1=Armed";
CM_ SG_ 997 ABS_ACTIVE "0=Inactive, 1=Active";
CM_ SG_ 997 ABS_ERROR "0=OK, 1=Error";
CM_ BO_ 998 "NOS and turbo speed sensor data";
CM_ SG_ 998 NOS_PRESSURE_SENSOR2 "Saturated at 14316.4 kPa, 14417.7 kPa absolute, 2076 psi.";
CM_ SG_ 998 NOS_PRESSURE_SENSOR3 "Saturated at 14316.4 kPa, 14417.7 kPa absolute, 2076 psi.";
CM_ SG_ 998 NOS_PRESSURE_SENSOR4 "Saturated at 14316.4 kPa, 14417.7 kPa absolute, 2076 psi.";
CM_ BO_ 999 "Generic sensor data";
CM_ SG_ 999 GENERIC_SENSOR1 "See Generic Sensors section.";
CM_ SG_ 999 GENERIC_SENSOR2 "See Generic Sensors section.";
CM_ SG_ 999 GENERIC_SENSOR3 "See Generic Sensors section.";
CM_ SG_ 999 GENERIC_SENSOR4 "See Generic Sensors section.";
CM_ BO_ 1000 "Generic sensor data";
CM_ SG_ 1000 GENERIC_SENSOR5 "See Generic Sensors section.";
CM_ SG_ 1000 GENERIC_SENSOR6 "See Generic Sensors section.";
CM_ SG_ 1000 GENERIC_SENSOR7 "See Generic Sensors section.";
CM_ SG_ 1000 GENERIC_SENSOR8 "See Generic Sensors section.";
CM_ BO_ 1001 "Generic sensor data and nitrous output states";
CM_ SG_ 1001 GENERIC_SENSOR9 "See Generic Sensors section.";
CM_ SG_ 1001 GENERIC_SENSOR10 "See Generic Sensors section.";
CM_ BO_ 1138 "Cruise control data";
CM_ SG_ 1143 LIMITER_METHOD_BYTE "Bit-field containing:
- Bits 7-4: ENGINE_LIMITER_METHOD (0=No Cut, 1=Fuel, 2=Ignition, 3=Fuel and Ignition)
- Bits 3-0: RPM_LIMITER_METHOD (0=No Cut, 1=Fuel, 2=Ignition, 3=Fuel and Ignition)

Use the following to extract values:
- ENGINE_LIMITER_METHOD = (LIMITER_METHOD_BYTE >> 4) & 0x0F
- RPM_LIMITER_METHOD = LIMITER_METHOD_BYTE & 0x0F";
CM_ BO_ 1776 "Tyre pressure data";
CM_ SG_ 1776 TYRE_PRESSURE_FL "0 = error (can be No Signal, Calibrating or Device Timeout) otherwise: y = x/10 - 101.3";
CM_ SG_ 1776 TYRE_PRESSURE_FR "0 = error (can be No Signal, Calibrating or Device Timeout) otherwise: y = x/10 - 101.3";
CM_ SG_ 1776 TYRE_PRESSURE_RL "0 = error (can be No Signal, Calibrating or Device Timeout) otherwise: y = x/10 - 101.3";
CM_ SG_ 1776 TYRE_PRESSURE_RR "0 = error (can be No Signal, Calibrating or Device Timeout) otherwise: y = x/10 - 101.3";
CM_ BO_ 1777 "Tyre temperature data";
CM_ SG_ 1777 TYRE_TEMPERATURE_FL "0 = error (can be No Signal, Calibrating or Device Timeout) otherwise: y = x/10";
CM_ SG_ 1777 TYRE_TEMPERATURE_FR "0 = error (can be No Signal, Calibrating or Device Timeout) otherwise: y = x/10";
CM_ SG_ 1777 TYRE_TEMPERATURE_RL "0 = error (can be No Signal, Calibrating or Device Timeout) otherwise: y = x/10";
CM_ SG_ 1777 TYRE_TEMPERATURE_RR "0 = error (can be No Signal, Calibrating or Device Timeout) otherwise: y = x/10";
CM_ BO_ 1778 "Tyre sensor battery data";
CM_ SG_ 1778 TYRE_SENSOR_BATT_VOLT_FL "0 = error (can be No Signal, Calibrating or Device Timeout) otherwise: y = x/1000";
CM_ SG_ 1778 TYRE_SENSOR_BATT_VOLT_FR "0 = error (can be No Signal, Calibrating or Device Timeout) otherwise: y = x/1000";
CM_ SG_ 1778 TYRE_SENSOR_BATT_VOLT_RL "0 = error (can be No Signal, Calibrating or Device Timeout) otherwise: y = x/1000";
CM_ SG_ 1778 TYRE_SENSOR_BATT_VOLT_RR "0 = error (can be No Signal, Calibrating or Device Timeout) otherwise: y = x/1000";
CM_ BO_ 1779 "Tyre recommended pressure and leak data and engine protection codes";
CM_ SG_ 1779 ENGINE_PROTECTION_SEVERITY_LEVEL "0 - Idle, 1 - Level 1, 2 - Level 2, 3 - Level 3";
CM_ SG_ 1779 ENGINE_PROTECTION_REASON_LETTER "This value is hexadecimal, and represents the OBDII DTC. The upper 2 bits determine which letter it is (0b00 = P, 0b01 = B, 0b10 = C, 0b11 = U) ";
CM_ BO_ 1784 "Motor control states";
CM_ SG_ 1784 EXHAUST_CUTOUT "-1: Input Error, 0: Disabled, 1: Closed, 2: Opening, 3: Open, 4: Closing, 5: Paused Part Way";
CM_ BO_ 1792 "PDM information";
CM_ SG_ 1792 PDM_DATA_BYTE_0 "See (PD16 CAN Protocol) for more detailed info.";

VAL_ 1779 ENGINE_PROTECTION_SEVERITY_LEVEL 0 "Idle" 1 "Level 1" 2 "Level 2" 3 "Level 3" ;
CM_ BO_ 1143 "Engine limiter data";
CM_ SG_ 1143 ENGINE_LIMITER_FUNCTION "Engine Limiting Functions table";
CM_ SG_ 1143 RPM_LIMITER_FUNCTION "Engine Limiting Functions table";
CM_ SG_ 1143 CUT_PERCENTAGE_FUNCTION "Engine Limiting Functions table";
CM_ BO_ 875 "Brake Pressure Front, NOS Pressure, Turbo Speed, Lat G";
CM_ BO_ 878 "Engine Limiting Active, Launch Control, Long G";
CM_ BO_ 880 "Vehicle Speed, Intake Cam Angle";
CM_ BO_ 882 "Batt V, Boost Target, Baro Pressure";
CM_ BO_ 992 "Engine Coolant, Air, Fuel, Oil Temps";
CM_ BO_ 993 "Gearbox, Dif Oil Temp, Fuel Compositio";
CM_ BO_ 1002 "Gearbox line pressure, injection and crank case pressure";
CM_ BO_ 1003 "Race timer and ignition angles";
CM_ BO_ 1004 "Torque Management values and setpoints";
CM_ SG_ 1004 TORQUE_MGMT_TRGT "Torque Management Driveshaft RPM Target";
CM_ SG_ 1004 TORQUE_MGMT_TRGT_ERR "Torque Management Driveshaft RPM Target Error";
CM_ SG_ 1004 TORQUE_MGMT_IGN_CORR "Torque Management Driveshaft RPM Target Error Ignition Correction";
CM_ SG_ 1004 TORQUE_MGMT_TIMED_IGN_CORR "Torque Management Driveshaft RPM Timed Ignition Correction";
CM_ BO_ 1136 "Wideband and Gear Position";
CM_ BO_ 1137 "Injector pressure, accel pedal and exhaust backpressure";
CM_ BO_ 1139 "Fuel Used, Antilag, TC, Fuel Pump, Nitrous, Water inj, cut method";
CM_ SG_ 1139 CUT_PERCENTAGE_METHOD "0 = No Cut 1 = Fuel 2 = Ignition 3 = Fuel and Ignition";
CM_ SG_ 1142 BRAKE_PRESSURE_DIFFERENCE "Brake Pressure Difference (Front minus Rear)";
CM_ BO_ 1782 "Trip Meter distance and fuel used";
CM_ BO_ 1783 "Generic output 1-20, Calc Air Temp, Water Inj Adv PWM";
CM_ SG_ 1783 GENERIC_OUTPUT_STATES "Generic Output 1 - 20 states. 0 = Off, 1 = On (at least 0.1% duty cycle if in Duty Cycle mode, or at least 1 Hz if in Frequency mode) Bit X = Generic output X+1";
VAL_ 1143 ENGINE_LIMITER_FUNCTION 0 "None" 1 "Hard Rev Limiting" 2 "Soft Rev Limiting" 3 "Spark Retard Limiting" 4 "Boost Limiting" 5 "Nitrous Retard" 6 "Flat Shift" 7 "Traction Control" 8 "Launch Control" 9 "Anti-Lag" 10 "Engine Protection" 11 "3-Step Launch" 12 "Rolling Launch" 13 "Burn Out" 14 "Water Inj." 15 "Gear Shift Cut" 16 "RPM Window Switch" 17 "Torque Management" 18 "Overrun Boost" 19 "Idle Control" ;
VAL_ 1143 RPM_LIMITER_FUNCTION 0 "None" 1 "Hard Rev Limiting" 2 "Soft Rev Limiting" 3 "Spark Retard Limiting" 4 "Boost Limiting" 5 "Nitrous Retard" 6 "Flat Shift" 7 "Traction Control" 8 "Launch Control" 9 "Anti-Lag" 10 "Engine Protection" 11 "3-Step Launch" 12 "Rolling Launch" 13 "Burn Out" 14 "Water Inj." 15 "Gear Shift Cut" 16 "RPM Window Switch" 17 "Torque Management" 18 "Overrun Boost" 19 "Idle Control" ;
VAL_ 1143 CUT_PERCENTAGE_FUNCTION 0 "None" 1 "Hard Rev Limiting" 2 "Soft Rev Limiting" 3 "Spark Retard Limiting" 4 "Boost Limiting" 5 "Nitrous Retard" 6 "Flat Shift" 7 "Traction Control" 8 "Launch Control" 9 "Anti-Lag" 10 "Engine Protection" 11 "3-Step Launch" 12 "Rolling Launch" 13 "Burn Out" 14 "Water Inj." 15 "Gear Shift Cut" 16 "RPM Window Switch" 17 "Torque Management" 18 "Overrun Boost" 19 "Idle Control" ;
CM_ SG_ 1139 FUEL_USED_BYTE4 "Bit-field containing various switch states:
- Bit 7: ROLLING_ANTILAG_SWITCH_STATE (0=Off, 1=On)
- Bit 6: ANTILAG_SWITCH_STATE (0=Off, 1=On)
- Bit 5: ANTILAG_OUTPUT_STATE (0=Off, 1=On)
- Bit 4: TRACTION_CONTROL_SWITCH_STATE (0=Off, 1=On)
- Bit 3: PRIMARY_FUEL_PUMP_OUTPUT_STATE (0=Off, 1=On)
- Bit 2: AUX1_FUEL_PUMP_OUTPUT_STATE (0=Off, 1=On)
- Bit 1: AUX2_FUEL_PUMP_OUTPUT_STATE (0=Off, 1=On)
- Bit 0: AUX3_FUEL_PUMP_OUTPUT_STATE (0=Off, 1=On)";

CM_ SG_ 1139 FUEL_USED_BYTE5 "Bit-field containing various switch states:
- Bit 7: NITROUS_ENABLE1_SWITCH_STATE (0=Off, 1=On)
- Bit 6: NITROUS_ENABLE1_OUTPUT_STATE (0=Off, 1=On)
- Bit 5: NITROUS_ENABLE2_SWITCH_STATE (0=Off, 1=On)
- Bit 4: NITROUS_ENABLE2_OUTPUT_STATE (0=Off, 1=On)
- Bit 3: NITROUS_ENABLE3_SWITCH_STATE (0=Off, 1=On)
- Bit 2: NITROUS_ENABLE3_OUTPUT_STATE (0=Off, 1=On)
- Bit 1: NITROUS_ENABLE4_SWITCH_STATE (0=Off, 1=On)
- Bit 0: NITROUS_ENABLE4_OUTPUT_STATE (0=Off, 1=On)";

CM_ SG_ 1139 FUEL_USED_BYTE6 "Bit-field containing various switch states:
- Bit 7: NITROUS_OVERRIDE1_SWITCH_STATE (0=Off, 1=On)
- Bit 6: NITROUS_OVERRIDE1_OUTPUT_STATE (0=Off, 1=On)
- Bit 5: NITROUS_OVERRIDE2_SWITCH_STATE (0=Off, 1=On)
- Bit 4: NITROUS_OVERRIDE2_OUTPUT_STATE (0=Off, 1=On)
- Bit 3: NITROUS_OVERRIDE3_SWITCH_STATE (0=Off, 1=On)
- Bit 2: NITROUS_OVERRIDE3_OUTPUT_STATE (0=Off, 1=On)
- Bit 1: NITROUS_OVERRIDE4_SWITCH_STATE (0=Off, 1=On)
- Bit 0: NITROUS_OVERRIDE4_OUTPUT_STATE (0=Off, 1=On)";

CM_ SG_ 1139 FUEL_USED_BYTE7 "Bit-field containing various states:
- Bit 7: WATER_INJECTION_ADVANCED_ENABLE_SWITCH_STATE (0=Off, 1=On)
- Bit 6: WATER_INJECTION_ADVANCED_ENABLE_OUTPUT_STATE (0=Off, 1=On)
- Bit 5: WATER_INJECTION_ADVANCED_OVERRIDE_SWITCH_STATE (0=Off, 1=On)
- Bit 4: WATER_INJECTION_ADVANCED_OVERRIDE_OUTPUT_STATE (0=Off, 1=On)
- Bits 3-0: CUT_PERCENTAGE_METHOD (0=No Cut, 1=Fuel, 2=Ignition, 3=Fuel and Ignition)";
VAL_ 1138 CRUISE_CONTROL_CONTROLLER_STATE 0 "Disabled" 1 "Inactive" 2 "Cruising" 3 "Accelerating" 4 "Decelerating" ;
VAL_ 997 ABS_ERROR 0 "OK" 1 "Error" ;
VAL_ 997 ABS_ACTIVE 0 "Inactive" 1 "Active" ;
VAL_ 997 ABS_ARMED 0 "Not Armed" 1 "Armed" ;
VAL_ 997 PIT_LANE_SPEED_LIMITER_ERROR 0 "OK" 1 "Error" ;
VAL_ 997 PIT_LANE_SPEED_LIMITER_ACTIVE 0 "Inactive" 1 "Active" ;
VAL_ 1136 GEAR -1 "Reverse" 0 "Neutral" 1 "1st" 2 "2nd" 3 "3rd" 4 "4th" 5 "5th" 6 "6th" 7 "7th" 8 "8th" 9 "9th" 10 "10th" 11 "11th" 12 "12th" ;
VAL_ 1136 GEAR_SELECTOR_POSITION -1 "Reverse" 0 "Neutral" 1 "1st" 2 "2nd" 3 "3rd" 4 "4th" 5 "5th" 6 "6th" 7 "7th" 8 "8th" 9 "9th" 10 "10th" 11 "11th" 12 "12th" ;
VAL_ 1784 EXHAUST_CUTOUT_STATE -1 "Input Error" 0 "Disabled" 1 "Closed" 2 "Opening" 3 "Open" 4 "Closing" 5 "Paused Part Way" ;
VAL_ 878 ENGINE_LIMITING_ACTIVE 0 "Off" 1 "On" ;
VAL_ 996 NEUTRAL_SWITCH 0 "Off" 1 "On" ;
VAL_ 996 REVERSE_SWITCH 0 "Off" 1 "On" ;
VAL_ 996 GEAR_SWITCH 0 "Off" 1 "On" ;
VAL_ 996 DECEL_CUT_ACTIVE 0 "Off" 1 "On" ;
VAL_ 996 TRANSIENT_THROTTLE_ACTIVE 0 "Off" 1 "On" ;
VAL_ 996 BRAKE_PEDAL_SWITCH 0 "Off" 1 "On" ;
VAL_ 996 CLUTCH_SWITCH 0 "Off" 1 "On" ;
VAL_ 996 OIL_PRESSURE_LIGHT 0 "Off" 1 "On" ;
VAL_ 996 LAUNCH_CONTROL_ACTIVE 0 "Off" 1 "On" ;
VAL_ 996 LAUNCH_CONTROL_SWITCH 0 "Off" 1 "On" ;
VAL_ 996 AUX_RPM_LIMITER_ACTIVE 0 "Off" 1 "On" ;
VAL_ 996 FLAT_SHIFT_SWITCH 0 "Off" 1 "On" ;
VAL_ 996 TORQUE_REDUCTION_ACTIVE 0 "Off" 1 "On" ;
VAL_ 996 TRACTION_CONTROL_ENABLED 0 "Off" 1 "On" ;
VAL_ 996 TRACTION_CONTROL_ACTIVE 0 "Off" 1 "On" ;
VAL_ 996 AIR_CON_REQUEST 0 "Off" 1 "On" ;
VAL_ 996 AIR_CON_OUTPUT 0 "Off" 1 "On" ;
VAL_ 996 THERMO_FAN4_ON 0 "Off" 1 "On" ;
VAL_ 996 THERMO_FAN3_ON 0 "Off" 1 "On" ;
VAL_ 996 THERMO_FAN2_ON 0 "Off" 1 "On" ;
VAL_ 996 THERMO_FAN1_ON 0 "Off" 1 "On" ;
VAL_ 996 CHECK_ENGINE_LIGHT 0 "Off" 1 "On" ;
VAL_ 996 BATTERY_LIGHT_ACTIVE 0 "Off" 1 "On" ;
VAL_ 996 HAND_BRAKE_STATE 0 "Off" 1 "On" ;
VAL_ 996 TRACTION_CONTROL_LIGHT 0 "Off" 1 "On" ;
VAL_ 997 IGNITION_SWITCH 0 "Off" 1 "On" ;
VAL_ 997 PIT_LANE_SPEED_LIMITER_SWITCH_STATE 0 "Off" 1 "On" ;
VAL_ 1139 ROLLING_ANTILAG_SWITCH_STATE 0 "Off" 1 "On" ;
VAL_ 1139 ANTILAG_SWITCH_STATE 0 "Off" 1 "On" ;
VAL_ 1139 ANTILAG_OUTPUT_STATE 0 "Off" 1 "On" ;
VAL_ 1139 TRACTION_CONTROL_SWITCH_STATE 0 "Off" 1 "On" ;
VAL_ 1139 PRIMARY_FUEL_PUMP_OUTPUT_STATE 0 "Off" 1 "On" ;
VAL_ 1139 AUX1_FUEL_PUMP_OUTPUT_STATE 0 "Off" 1 "On" ;
VAL_ 1139 AUX2_FUEL_PUMP_OUTPUT_STATE 0 "Off" 1 "On" ;
VAL_ 1139 AUX3_FUEL_PUMP_OUTPUT_STATE 0 "Off" 1 "On" ;
VAL_ 1001 NITROUS_STAGE1_OUTPUT_STATE 0 "Off" 1 "On" ;
VAL_ 1001 NITROUS_STAGE2_OUTPUT_STATE 0 "Off" 1 "On" ;
VAL_ 1001 NITROUS_STAGE3_OUTPUT_STATE 0 "Off" 1 "On" ;
VAL_ 1001 NITROUS_STAGE4_OUTPUT_STATE 0 "Off" 1 "On" ;
VAL_ 1001 NITROUS_STAGE5_OUTPUT_STATE 0 "Off" 1 "On" ;
VAL_ 1001 NITROUS_STAGE6_OUTPUT_STATE 0 "Off" 1 "On" ;
VAL_ 1001 WATER_INJECTION_ADVANCED_OUTPUT_STATE 0 "Off" 1 "On" ;
VAL_ 1139 NITROUS_ENABLE1_SWITCH_STATE 0 "Off" 1 "On" ;
VAL_ 1139 NITROUS_ENABLE1_OUTPUT_STATE 0 "Off" 1 "On" ;
VAL_ 1139 NITROUS_ENABLE2_SWITCH_STATE 0 "Off" 1 "On" ;
VAL_ 1139 NITROUS_ENABLE2_OUTPUT_STATE 0 "Off" 1 "On" ;
VAL_ 1139 NITROUS_ENABLE3_SWITCH_STATE 0 "Off" 1 "On" ;
VAL_ 1139 NITROUS_ENABLE3_OUTPUT_STATE 0 "Off" 1 "On" ;
VAL_ 1139 NITROUS_ENABLE4_SWITCH_STATE 0 "Off" 1 "On" ;
VAL_ 1139 NITROUS_ENABLE4_OUTPUT_STATE 0 "Off" 1 "On" ;
VAL_ 1139 NITROUS_OVERRIDE1_SWITCH_STATE 0 "Off" 1 "On" ;
VAL_ 1139 NITROUS_OVERRIDE1_OUTPUT_STATE 0 "Off" 1 "On" ;
VAL_ 1139 NITROUS_OVERRIDE2_SWITCH_STATE 0 "Off" 1 "On" ;
VAL_ 1139 NITROUS_OVERRIDE2_OUTPUT_STATE 0 "Off" 1 "On" ;
VAL_ 1139 NITROUS_OVERRIDE3_SWITCH_STATE 0 "Off" 1 "On" ;
VAL_ 1139 NITROUS_OVERRIDE3_OUTPUT_STATE 0 "Off" 1 "On" ;
VAL_ 1139 NITROUS_OVERRIDE4_SWITCH_STATE 0 "Off" 1 "On" ;
VAL_ 1139 NITROUS_OVERRIDE4_OUTPUT_STATE 0 "Off" 1 "On" ;
VAL_ 1139 WATER_INJECTION_ADVANCED_ENABLE_SWITCH_STATE 0 "Off" 1 "On" ;
VAL_ 1139 WATER_INJECTION_ADVANCED_ENABLE_OUTPUT_STATE 0 "Off" 1 "On" ;
VAL_ 1139 WATER_INJECTION_ADVANCED_OVERRIDE_SWITCH_STATE 0 "Off" 1 "On" ;
VAL_ 1139 WATER_INJECTION_ADVANCED_OVERRIDE_OUTPUT_STATE 0 "Off" 1 "On" ;
VAL_ 1779 REAR_RIGHT_TYRE_AIR_LEAK_DETECTED 0 "No Leak" 1 "Leak Detected" ;
VAL_ 1779 REAR_LEFT_TYRE_AIR_LEAK_DETECTED 0 "No Leak" 1 "Leak Detected" ;
VAL_ 1779 FRONT_RIGHT_TYRE_AIR_LEAK_DETECTED 0 "No Leak" 1 "Leak Detected" ;
VAL_ 1779 FRONT_LEFT_TYRE_AIR_LEAK_DETECTED 0 "No Leak" 1 "Leak Detected" ;
VAL_ 1780 PARK_LIGHT_STATE 0 "Off" 1 "On" ;
VAL_ 1780 HEAD_LIGHT_STATE 0 "Off" 1 "On" ;
VAL_ 1780 HIGH_BEAM_LIGHT_STATE 0 "Off" 1 "On" ;
VAL_ 1780 LEFT_INDICATOR_STATE 0 "Off" 1 "On" ;
VAL_ 1780 RIGHT_INDICATOR_STATE 0 "Off" 1 "On" ;
